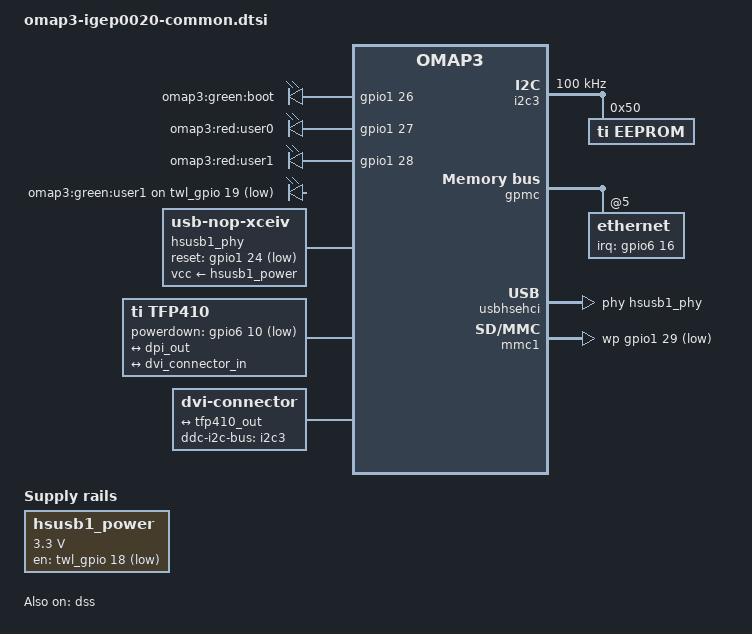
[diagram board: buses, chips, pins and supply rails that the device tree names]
#include "omap3-igep.dtsi"
#include "omap-gpmc-smsc9221.dtsi"
/ {
	leds {
		pinctrl-names = "default";
		pinctrl-0 = <&leds_pins>;
		compatible = "gpio-leds";
		boot {
			 label = "omap3:green:boot";
			 gpios = <&gpio1 26 GPIO_ACTIVE_HIGH>;
			 default-state = "on";
		};
		user0 {
			 label = "omap3:red:user0";
			 gpios = <&gpio1 27 GPIO_ACTIVE_HIGH>;
			 default-state = "off";
		};
		user1 {
			 label = "omap3:red:user1";
			 gpios = <&gpio1 28 GPIO_ACTIVE_HIGH>;
			 default-state = "off";
		};
		user2 {
			label = "omap3:green:user1";
			gpios = <&twl_gpio 19 GPIO_ACTIVE_LOW>;
		};
	};
	hsusb1_power: hsusb1_power_reg {
		compatible = "regulator-fixed";
		regulator-name = "hsusb1_vbus";
		regulator-min-microvolt = <3300000>;
		regulator-max-microvolt = <3300000>;
		gpio = <&twl_gpio 18 GPIO_ACTIVE_LOW>;	 
		startup-delay-us = <70000>;
	};
	hsusb1_phy: hsusb1_phy {
		compatible = "usb-nop-xceiv";
		reset-gpios = <&gpio1 24 GPIO_ACTIVE_LOW>;  
		vcc-supply = <&hsusb1_power>;
		#phy-cells = <0>;
	};
	tfp410: encoder {
		compatible = "ti,tfp410";
		powerdown-gpios = <&gpio6 10 GPIO_ACTIVE_LOW>;  
		ports {
			#address-cells = <1>;
			#size-cells = <0>;
			port@0 {
				reg = <0>;
				tfp410_in: endpoint {
					remote-endpoint = <&dpi_out>;
				};
			};
			port@1 {
				reg = <1>;
				tfp410_out: endpoint {
					remote-endpoint = <&dvi_connector_in>;
				};
			};
		};
	};
	dvi0: connector {
		compatible = "dvi-connector";
		label = "dvi";
		digital;
		ddc-i2c-bus = <&i2c3>;
		port {
			dvi_connector_in: endpoint {
				remote-endpoint = <&tfp410_out>;
			};
		};
	};
};
&omap3_pmx_core {
	pinctrl-names = "default";
	pinctrl-0 = <
		&tfp410_pins
		&dss_dpi_pins
	>;
	tfp410_pins: tfp410-pins {
		pinctrl-single,pins = <
			OMAP3_CORE1_IOPAD(0x21c6, PIN_OUTPUT | MUX_MODE4)    
		>;
	};
	dss_dpi_pins: dss-dpi-pins {
		pinctrl-single,pins = <
			OMAP3_CORE1_IOPAD(0x20d4, PIN_OUTPUT | MUX_MODE0)    
			OMAP3_CORE1_IOPAD(0x20d6, PIN_OUTPUT | MUX_MODE0)    
			OMAP3_CORE1_IOPAD(0x20d8, PIN_OUTPUT | MUX_MODE0)    
			OMAP3_CORE1_IOPAD(0x20da, PIN_OUTPUT | MUX_MODE0)    
			OMAP3_CORE1_IOPAD(0x20dc, PIN_OUTPUT | MUX_MODE0)    
			OMAP3_CORE1_IOPAD(0x20de, PIN_OUTPUT | MUX_MODE0)    
			OMAP3_CORE1_IOPAD(0x20e0, PIN_OUTPUT | MUX_MODE0)    
			OMAP3_CORE1_IOPAD(0x20e2, PIN_OUTPUT | MUX_MODE0)    
			OMAP3_CORE1_IOPAD(0x20e4, PIN_OUTPUT | MUX_MODE0)    
			OMAP3_CORE1_IOPAD(0x20e6, PIN_OUTPUT | MUX_MODE0)    
			OMAP3_CORE1_IOPAD(0x20e8, PIN_OUTPUT | MUX_MODE0)    
			OMAP3_CORE1_IOPAD(0x20ea, PIN_OUTPUT | MUX_MODE0)    
			OMAP3_CORE1_IOPAD(0x20ec, PIN_OUTPUT | MUX_MODE0)    
			OMAP3_CORE1_IOPAD(0x20ee, PIN_OUTPUT | MUX_MODE0)    
			OMAP3_CORE1_IOPAD(0x20f0, PIN_OUTPUT | MUX_MODE0)    
			OMAP3_CORE1_IOPAD(0x20f2, PIN_OUTPUT | MUX_MODE0)    
			OMAP3_CORE1_IOPAD(0x20f4, PIN_OUTPUT | MUX_MODE0)    
			OMAP3_CORE1_IOPAD(0x20f6, PIN_OUTPUT | MUX_MODE0)    
			OMAP3_CORE1_IOPAD(0x20f8, PIN_OUTPUT | MUX_MODE0)    
			OMAP3_CORE1_IOPAD(0x20fa, PIN_OUTPUT | MUX_MODE0)    
			OMAP3_CORE1_IOPAD(0x20fc, PIN_OUTPUT | MUX_MODE0)    
			OMAP3_CORE1_IOPAD(0x20fe, PIN_OUTPUT | MUX_MODE0)    
			OMAP3_CORE1_IOPAD(0x2100, PIN_OUTPUT | MUX_MODE0)    
			OMAP3_CORE1_IOPAD(0x2102, PIN_OUTPUT | MUX_MODE0)    
			OMAP3_CORE1_IOPAD(0x2104, PIN_OUTPUT | MUX_MODE0)    
			OMAP3_CORE1_IOPAD(0x2106, PIN_OUTPUT | MUX_MODE0)    
			OMAP3_CORE1_IOPAD(0x2108, PIN_OUTPUT | MUX_MODE0)    
			OMAP3_CORE1_IOPAD(0x210a, PIN_OUTPUT | MUX_MODE0)    
		>;
	};
	uart2_pins: uart2-pins {
		pinctrl-single,pins = <
			OMAP3_CORE1_IOPAD(0x2174, PIN_INPUT | MUX_MODE0)	 
			OMAP3_CORE1_IOPAD(0x2176, PIN_OUTPUT | MUX_MODE0)	 
			OMAP3_CORE1_IOPAD(0x2178, PIN_OUTPUT | MUX_MODE0)	 
			OMAP3_CORE1_IOPAD(0x217a, PIN_INPUT | MUX_MODE0)	 
		>;
	};
	smsc9221_pins: smsc9221-pins {
		pinctrl-single,pins = <
			OMAP3_CORE1_IOPAD(0x21d2, PIN_INPUT | MUX_MODE4)	 
		>;
	};
};
&omap3_pmx_core2 {
	pinctrl-names = "default";
	pinctrl-0 = <
		&hsusbb1_pins
	>;
	hsusbb1_pins: hsusbb1-pins {
		pinctrl-single,pins = <
			OMAP3630_CORE2_IOPAD(0x25da, PIN_OUTPUT | MUX_MODE3)		 
			OMAP3630_CORE2_IOPAD(0x25d8, PIN_OUTPUT | MUX_MODE3)		 
			OMAP3630_CORE2_IOPAD(0x25ec, PIN_INPUT_PULLDOWN | MUX_MODE3)	 
			OMAP3630_CORE2_IOPAD(0x25ee, PIN_INPUT_PULLDOWN | MUX_MODE3)	 
			OMAP3630_CORE2_IOPAD(0x25dc, PIN_INPUT_PULLDOWN | MUX_MODE3)	 
			OMAP3630_CORE2_IOPAD(0x25de, PIN_INPUT_PULLDOWN | MUX_MODE3)	 
			OMAP3630_CORE2_IOPAD(0x25e0, PIN_INPUT_PULLDOWN | MUX_MODE3)	 
			OMAP3630_CORE2_IOPAD(0x25e2, PIN_INPUT_PULLDOWN | MUX_MODE3)	 
			OMAP3630_CORE2_IOPAD(0x25e4, PIN_INPUT_PULLDOWN | MUX_MODE3)	 
			OMAP3630_CORE2_IOPAD(0x25e6, PIN_INPUT_PULLDOWN | MUX_MODE3)	 
			OMAP3630_CORE2_IOPAD(0x25e8, PIN_INPUT_PULLDOWN | MUX_MODE3)	 
			OMAP3630_CORE2_IOPAD(0x25ea, PIN_INPUT_PULLDOWN | MUX_MODE3)	 
		>;
	};
	leds_pins: leds-pins {
		pinctrl-single,pins = <
			OMAP3630_CORE2_IOPAD(0x25f4, PIN_OUTPUT | MUX_MODE4)  
			OMAP3630_CORE2_IOPAD(0x25f6, PIN_OUTPUT | MUX_MODE4)  
			OMAP3630_CORE2_IOPAD(0x25f8, PIN_OUTPUT | MUX_MODE4)  
		>;
	};
	mmc1_wp_pins: mmc1-cd-pins {
		pinctrl-single,pins = <
			OMAP3630_CORE2_IOPAD(0x25fa, PIN_INPUT | MUX_MODE4)    
		>;
	};
};
&i2c3 {
	clock-frequency = <100000>;
	eeprom@50 {
		compatible = "ti,eeprom";
		reg = <0x50>;
	};
};
&gpmc {
	ranges = <0 0 0x30000000 0x01000000>,	 
		 <5 0 0x2c000000 0x01000000>;	 
	ethernet@gpmc {
		pinctrl-names = "default";
		pinctrl-0 = <&smsc9221_pins>;
		reg = <5 0 0xff>;
		interrupt-parent = <&gpio6>;
		interrupts = <16 IRQ_TYPE_LEVEL_LOW>;
	};
};
&uart2 {
	pinctrl-names = "default";
	pinctrl-0 = <&uart2_pins>;
};
&usbhshost {
	port1-mode = "ehci-phy";
};
&usbhsehci {
	phys = <&hsusb1_phy>;
};
&vpll2 {
	regulator-name = "vdds_dsi";
};
&dss {
	status = "okay";
	port {
		dpi_out: endpoint {
			remote-endpoint = <&tfp410_in>;
			data-lines = <24>;
		};
	};
};
&mmc1 {
	pinctrl-0 = <&mmc1_pins &mmc1_wp_pins>;
	wp-gpios = <&gpio1 29 GPIO_ACTIVE_LOW>;	 
};
